# SAM9X75D1GN2 device description
Architecture: ARM926EJ-S; Family: SAM9; Series: SAM9X7
Registers are 32-bit, read-write, reset 0x0 unless marked. A register's access mark holds for its fields unless they carry their own. Offsets are from the block's base; [hi:lo] are bit positions; lines under a group give offsets from that group; {n}, {i} and the like mark numbered series.

## GFX2D — 2D Graphics Engine
Instances: GFX2D 0xF0018000
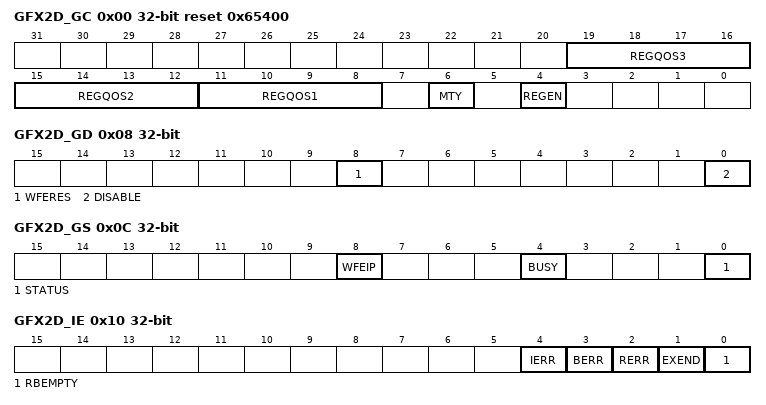
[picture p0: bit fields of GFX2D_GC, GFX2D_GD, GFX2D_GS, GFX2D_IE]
0x00 GFX2D_GC reset 0x65400 — Global Configuration Register
  [19:16] REGQOS3 — Regulation for QoS Level 3
  [15:12] REGQOS2 — Regulation for QoS Level 2
  [11:8] REGQOS1 — Regulation for QoS Level 1
  [6] MTY — Memory Tile Access
    0=GFX2D uses tile accesses; 1=GFX2D uses linear accesses
  [4] REGEN — Outstanding Regulation Enable
    0=Outstanding Regulation is disabled; 1=Outstanding Regulation is enabled
0x04 GFX2D_GE wo — Global Enable Register
  [0] ENABLE — GFX2D Enable
    0=No effect; 1=Enables the GFX2D controller. This operation is permitted if the global status bit was read as '0'.
0x08 GFX2D_GD wo — Global Disable Register
  [8] WFERES — WFE Software Resume bit
    0=No effect; 1=Exits the WFE state in software
  [0] DISABLE — GFX2D Disable Bit
    0=No effect; 1=Disables the graphics engine
0x0C GFX2D_GS ro — Global Status Register
  [8] WFEIP — Wait For Event Status bit
    0=The graphics core is running; 1=The graphics core is waiting for an event
  [4] BUSY — GFX2D Busy Bit
    0=The graphics core is in idle state; 1=The graphics core is busy
  [0] STATUS — GFX2D Status Bit
    0=The graphics engine is disabled; 1=The graphics engine is enabled
0x10 GFX2D_IE wo — Interrupt Enable Register
  [4] IERR — Illegal Instruction Interrupt Enable Bit
  [3] BERR — Write Data Bus Error Interrupt Enable Bit
  [2] RERR — Read Data Bus Error Interrupt Enable Bit
  [1] EXEND — End of Execution Interrupt Enable Bit
  [0] RBEMPTY — Ring Buffer Empty Interrupt Enable Bit
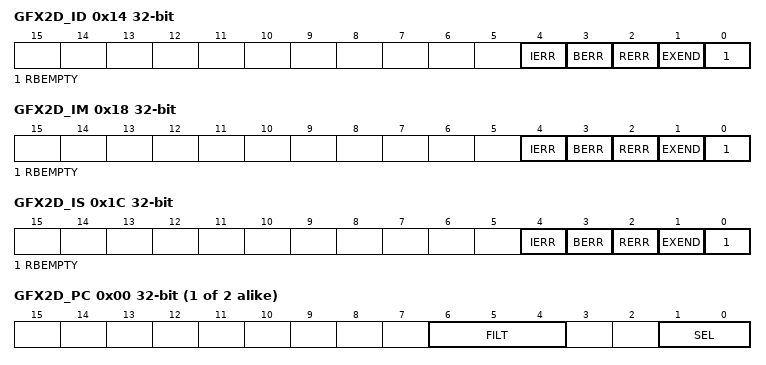
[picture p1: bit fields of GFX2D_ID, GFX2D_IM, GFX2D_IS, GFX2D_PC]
0x14 GFX2D_ID wo — Interrupt Disable Register
  [4] IERR — Illegal Instruction Interrupt Disable bit
  [3] BERR — Write Access Error Interrupt Disable bit
  [2] RERR — Read Access Error Interrupt Disable Bit
  [1] EXEND — End of Execution Interrupt Disable Bit
  [0] RBEMPTY — Ring Buffer Empty Interrupt Disable Bit
0x18 GFX2D_IM ro — Interrupt Mask Register
  [4] IERR — Illegal Instruction Interrupt Mask Bit
  [3] BERR — Write Error Interrupt Mask Bit
  [2] RERR — Read Error Interrupt Mask Bit
  [1] EXEND — Execution Ended Empty Interrupt Mask Bit
  [0] RBEMPTY — Ring Buffer Empty Interrupt Mask Bit
0x1C GFX2D_IS ro — Interrupt Status Register
  [4] IERR — Illegal Instruction Interrupt Status Bit
    0=Either the illegal instruction interrupt source is masked or no illegal instruction interrupt is pending; 1=An illegal instruction interrupt is pending
  [3] BERR — Write Error Interrupt Status Bit
    0=Either the interrupt source is masked or no write error interrupt is pending; 1=A Write Error interrupt is pending
  [2] RERR — Read Error Interrupt Status Bit
    0=Either the read error interrupt source is masked or no read error interrupt is pending; 1=A read error interrupt is pending
  [1] EXEND — End of Execution Status Bit
    0=Either the interrupt source is masked or no end of execution interrupt is pending; 1=End of execution interrupt is pending (i.e. when GFX2D_GS.BUSY is set to 0).
  [0] RBEMPTY — Ring Buffer Empty Interrupt Status Bit
    0=The ring buffer empty interrupt has not occurred; 1=The ring buffer empty interrupt has occurred since the last read of the status register
{0x20+8i} GFX2D_SUB0[{i}] (i=0..1) group
  0x00 GFX2D_PC — Performance Configuration x Register
    [6:4] FILT — Filter Configuration
      0=DISABLED (The filter is disabled.); {v}=QOS{v-1} (Events are valid when input QoS is equal to {v-1}.) (v=1..4)
    [1:0] SEL — Performance Metrics Selection
      0=DISABLED (The performance counter is disabled and reset.); 1=READ (The performance counter is incremented when a Read access is performed.); 2=WRITE (The performance counter is incremented when a Write access is performed.); 3=CYCLE (Number of clock cycles)
  0x04 GFX2D_MC ro — Metrics Counter x Register
    [31:0] COUNTER — Metrics Counter
0x30 GFX2D_BASE — Ring Buffer Base Register
  [31:8] BASE
0x34 GFX2D_LEN — Ring Buffer Length Register
  [3:0] LEN — Ring Buffer Length Multiplier
0x38 GFX2D_HEAD — Ring Buffer Head Register
  [9:0] HEAD — Ring Buffer Head Pointer
0x3C GFX2D_TAIL — Ring Buffer Tail Register
  [9:0] TAIL — Ring Buffer Tail Pointer
{0x40+0x10*i} GFX2D_CHID[{i}] (i=0..3) group
  0x00 GFX2D_PA — Surface Physical Address Register
    [31:0] PA — Surface Physical Start Address
  0x04 GFX2D_PITCH — Surface Pitch Register
    [15:0] PITCH — Surface Pitch
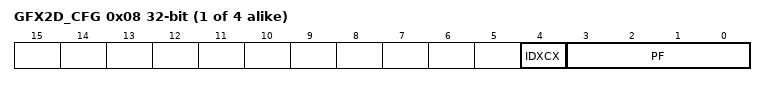
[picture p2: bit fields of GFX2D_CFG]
  0x08 GFX2D_CFG — Surface Configuration Register
    [4] IDXCX — Color Look-Up Table Selection
      0=The indexed color is retrieved in Color Look-Up Table 0; 1=The indexed color is retrieved in Color Look-Up Table 1
    [3:0] PF — Pixel Format
      0=A4IDX4 (4-bit indexed color, with 4-bit alpha value); 1=A8 (8 bits per pixel alpha, with user-defined constant color); 2=IDX8 (8 bits indexed color, uses the Color Look-Up Table to expand to true color); 3=A8IDX8 (8-bit indexed color, with 8-bit alpha value); 4=RGB12 (12 bits per pixel, 4 bits per color channel); 5=ARGB16 (16 bits per pixel with 4-bit width alpha value, and 4 bits per color channel); 6=RGB15 (15 bits per pixel, 5 bits per color channel); 7=TRGB16 (16 bits per pixel, 5 bits for the red and blue channels and 6 bits for the green channel); 8=RGBT16 (16 bits per pixel, with 1 bit for transparency and 5 bits for color channels); 9=RGB16 (16 bits per pixel, 5 bits for the red and blue channels and 6 bits for the green channel); 10=RGB24 (24 bits per pixel, 8 bits for alpha and color channels); 11=ARGB32 (32 bits per pixel, 8 bits for alpha and color channels); 12=RGBA32 (32 bits per pixel, 8 bits for alpha and color channels)
